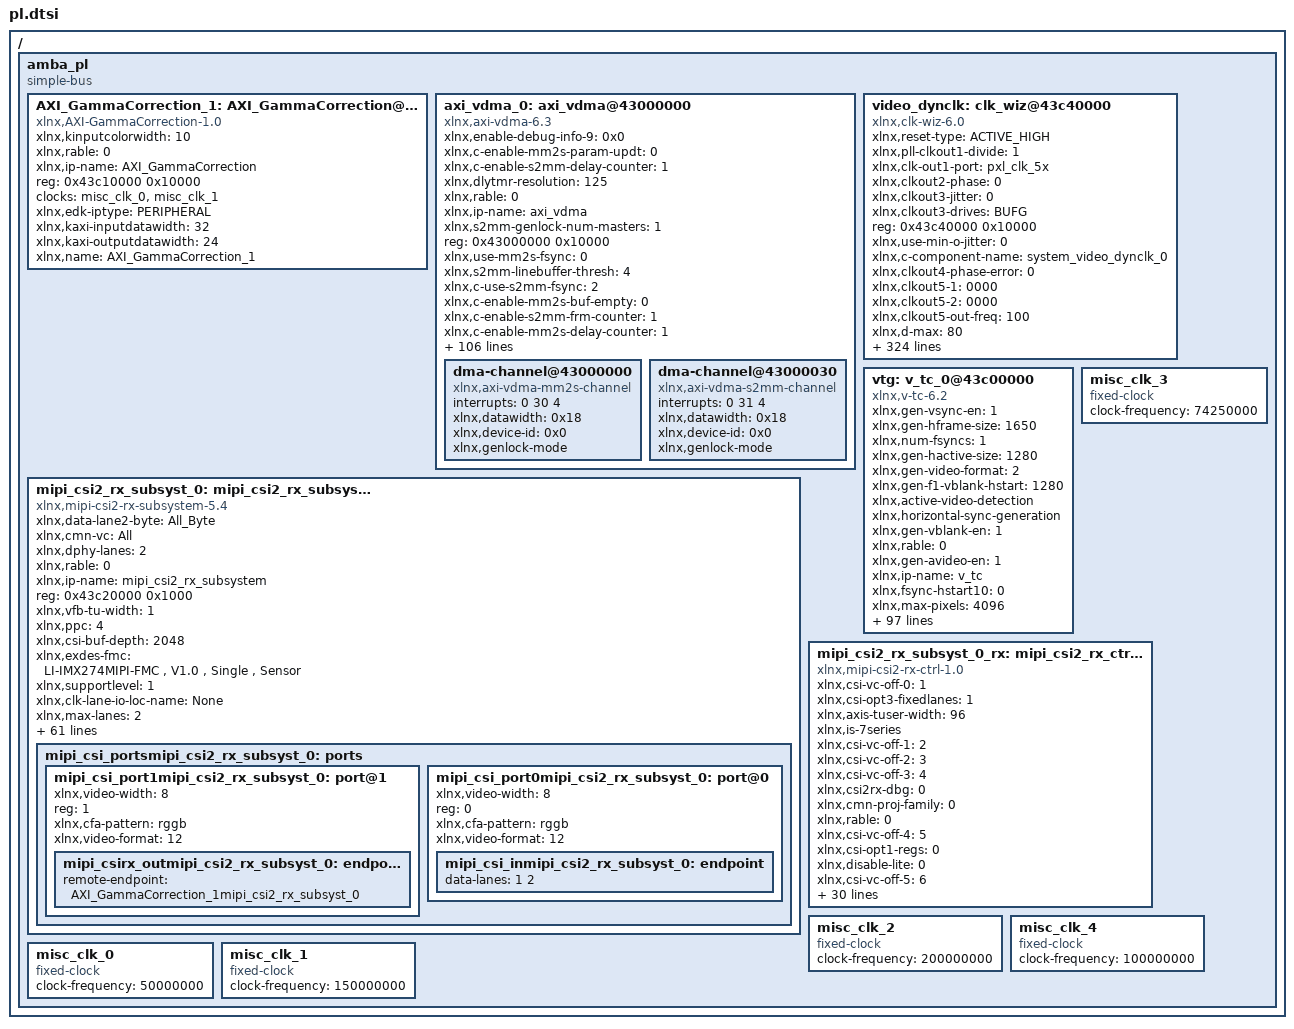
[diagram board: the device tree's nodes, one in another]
/ {
	amba_pl: amba_pl {
		ranges;
		compatible = "simple-bus";
		#address-cells = <1>;
		#size-cells = <1>;
		AXI_GammaCorrection_1: AXI_GammaCorrection@43c10000 {
			compatible = "xlnx,AXI-GammaCorrection-1.0";
			xlnx,kinputcolorwidth = <10>;
			xlnx,rable = <0>;
			xlnx,ip-name = "AXI_GammaCorrection";
			reg = <0x43c10000 0x10000>;
			clocks = <&misc_clk_0>, <&misc_clk_1>;
			xlnx,edk-iptype = "PERIPHERAL";
			xlnx,kaxi-inputdatawidth = <32>;
			xlnx,kaxi-outputdatawidth = <24>;
			status = "okay";
			clock-names = "AxiLiteClk" , "StreamClk";
			xlnx,name = "AXI_GammaCorrection_1";
		};
		axi_vdma_0: axi_vdma@43000000 {
			xlnx,enable-debug-info-9 = <0x0>;
			xlnx,c-enable-mm2s-param-updt = <0>;
			xlnx,c-enable-s2mm-delay-counter = <1>;
			xlnx,dlytmr-resolution = <125>;
			xlnx,rable = <0>;
			xlnx,ip-name = "axi_vdma";
			xlnx,s2mm-genlock-num-masters = <1>;
			reg = <0x43000000 0x10000>;
			xlnx,use-mm2s-fsync = <0>;
			xlnx,s2mm-linebuffer-thresh = <4>;
			xlnx,c-use-s2mm-fsync = <2>;
			xlnx,c-enable-mm2s-buf-empty = <0>;
			xlnx,c-enable-s2mm-frm-counter = <1>;
			xlnx,c-enable-mm2s-delay-counter = <1>;
			xlnx,c-dlytmr-resolution = <125>;
			xlnx,c-enable-s2mm-buf-full = <0>;
			xlnx,dynamic-resolution = <1>;
			interrupt-names = "mm2s_introut" , "s2mm_introut";
			xlnx,s2mm-sof-enable = <0x1>;
			xlnx,mm2s-genlock-num-masters = <1>;
			xlnx,c-s2mm-genlock-num-masters = <1>;
			xlnx,c-enable-s2mm-fsync-out = <0>;
			xlnx,mm2s-linebuffer-thresh = <4>;
			xlnx,c-use-mm2s-fsync = <0>;
			xlnx,c-s2mm-linebuffer-thresh = <4>;
			xlnx,c-enable-mm2s-frm-counter = <1>;
			compatible = "xlnx,axi-vdma-6.3" , "xlnx,axi-vdma-1.00.a";
			xlnx,c-m-axis-mm2s-tdata-width = <24>;
			xlnx,c-enable-all = <0>;
			interrupt-parent = <&intc>;
			xlnx,s2mm-max-burst-length = <8>;
			xlnx,c-dynamic-resolution = <1>;
			xlnx,c-enable-s2mm-rst-out = <0>;
			xlnx,mm2s-sof-enable = <1>;
			xlnx,include-s2mm-dre = <0x0>;
			xlnx,c-s2mm-sof-enable = <1>;
			xlnx,c-enable-mm2s-fsync-out = <0>;
			xlnx,c-mm2s-genlock-num-masters = <1>;
			xlnx,c-mm2s-linebuffer-thresh = <4>;
			xlnx,c-enable-tstvec = <0>;
			xlnx,mm2s-max-burst-length = <8>;
			xlnx,c-s2mm-max-burst-length = <8>;
			status = "okay";
			xlnx,c-enable-mm2s-rst-out = <0>;
			xlnx,include-mm2s-dre = <0x0>;
			xlnx,c-include-s2mm-dre = <0>;
			xlnx,c-mm2s-sof-enable = <1>;
			xlnx,name = "axi_vdma_0";
			xlnx,c-enable-s2mm-frmstr-reg = <0>;
			interrupts = < 0 30 4 0 31 4 >;
			xlnx,c-include-sg = <0>;
			xlnx,flush-on-fsync = <0x1>;
			xlnx,c-m-axi-s2mm-data-width = <64>;
			xlnx,c-enable-s2mm-sts-reg = <0>;
			xlnx,include-s2mm-sf = <1>;
			xlnx,c-mm2s-max-burst-length = <8>;
			xlnx,s2mm-linebuffer-depth = <0x400>;
			xlnx,include-s2mm = <0x1>;
			xlnx,c-include-mm2s-dre = <0>;
			clocks = <&misc_clk_1>, <&misc_clk_1>, <&misc_clk_1>, <&misc_clk_0>, <&misc_clk_1>;
			xlnx,c-enable-mm2s-frmstr-reg = <0>;
			xlnx,enable-debug-info-10 = <0>;
			xlnx,addrwidth = <0x20>;
			xlnx,enable-debug-info-11 = <0>;
			xlnx,enable-debug-info-12 = <0>;
			xlnx,edk-iptype = "PERIPHERAL";
			xlnx,c-flush-on-fsync = <1>;
			xlnx,c-m-axi-mm2s-data-width = <64>;
			xlnx,use-fsync = <1>;
			xlnx,s2mm-genlock-repeat-en = <1>;
			xlnx,enable-vert-flip = <0x0>;
			xlnx,enable-debug-info-13 = <0x0>;
			xlnx,include-mm2s-sf = <0>;
			xlnx,include-internal-genlock = <0x1>;
			xlnx,enable-debug-info-14 = <0x1>;
			xlnx,c-include-s2mm-sf = <1>;
			clock-names = "m_axi_mm2s_aclk" , "m_axi_s2mm_aclk" , "m_axis_mm2s_aclk" , "s_axi_lite_aclk" , "s_axis_s2mm_aclk";
			xlnx,enable-debug-info-15 = <0x1>;
			xlnx,mm2s-linebuffer-depth = <0x400>;
			xlnx,include-mm2s = <0x1>;
			xlnx,c-single-interface = <0>;
			xlnx,c-s2mm-linebuffer-depth = <1024>;
			xlnx,c-addr-width = <32>;
			xlnx,c-include-s2mm = <1>;
			xlnx,s2mm-genlock-mode = <0x2>;
			xlnx,c-s-axis-s2mm-tdata-width = <24>;
			xlnx,flush-fsync = <0x1>;
			xlnx,select-xpm = <0>;
			xlnx,s2mm-data-width = <0x40>;
			xlnx,num-fstores = <0x3>;
			xlnx,enable-vidparam-reads = <0x1>;
			xlnx,mm2s-genlock-repeat-en = <0>;
			xlnx,c-use-fsync = <1>;
			xlnx,c-s2mm-genlock-repeat-en = <1>;
			xlnx,c-enable-vert-flip = <0>;
			xlnx,prmry-is-aclk-async = <0>;
			xlnx,c-include-internal-genlock = <1>;
			xlnx,c-include-mm2s-sf = <0>;
			xlnx,s2mm-tdata-width = <0x18>;
			xlnx,enable-vidprmtr-reads = <1>;
			xlnx,c-include-mm2s = <1>;
			xlnx,c-mm2s-linebuffer-depth = <1024>;
			xlnx,mm2s-genlock-mode = <0x3>;
			xlnx,enable-debug-info-0 = <0>;
			xlnx,enable-debug-all = <0x0>;
			xlnx,c-s2mm-genlock-mode = <2>;
			xlnx,enable-debug-info-1 = <0x0>;
			xlnx,mm2s-data-width = <0x40>;
			xlnx,enable-debug-info-2 = <0>;
			xlnx,c-enable-s2mm-param-updt = <0>;
			xlnx,c-num-fstores = <3>;
			xlnx,enable-debug-info-3 = <0>;
			xlnx,enable-debug-info-4 = <0>;
			xlnx,c-mm2s-genlock-repeat-en = <0>;
			xlnx,enable-debug-info-5 = <0x0>;
			xlnx,c-prmry-is-aclk-async = <0>;
			xlnx,mm2s-tdata-width = <0x18>;
			xlnx,enable-debug-info-6 = <0x1>;
			xlnx,enable-debug-info-7 = <0x1>;
			xlnx,c-enable-vidprmtr-reads = <1>;
			xlnx,use-s2mm-fsync = <2>;
			xlnx,enable-debug-info-8 = <0>;
			xlnx,c-mm2s-genlock-mode = <3>;
			dma-channel@43000000 {
				interrupts = < 0 30 4 >;
				xlnx,datawidth = <0x18>;
				xlnx,device-id = <0x0>;
				compatible = "xlnx,axi-vdma-mm2s-channel";
				xlnx,genlock-mode;
			};
			dma-channel@43000030 {
				interrupts = < 0 31 4 >;
				xlnx,datawidth = <0x18>;
				xlnx,device-id = <0x0>;
				compatible = "xlnx,axi-vdma-s2mm-channel";
				xlnx,genlock-mode;
			};
		};
		mipi_csi2_rx_subsyst_0: mipi_csi2_rx_subsystem@43c20000 {
			xlnx,data-lane2-byte = "All_Byte";
			xlnx,cmn-vc = "All";
			xlnx,dphy-lanes = <2>;
			xlnx,rable = <0>;
			xlnx,ip-name = "mipi_csi2_rx_subsystem";
			reg = <0x43c20000 0x1000>;
			xlnx,vfb-tu-width = <1>;
			xlnx,ppc = <4>;
			xlnx,csi-buf-depth = <2048>;
			xlnx,exdes-fmc = "LI-IMX274MIPI-FMC , V1.0 , Single , Sensor";
			xlnx,supportlevel = <1>;
			xlnx,clk-lane-io-loc-name = "None";
			xlnx,max-lanes = <2>;
			xlnx,clk-lane-io-loc = "None";
			xlnx,esc-timeout = <25600>;
			xlnx,cmn-inc-vfb;
			xlnx,axis-tuser-width = <96>;
			compatible = "xlnx,mipi-csi2-rx-subsystem-5.4" , "xlnx,mipi-csi2-rx-subsystem-5.0";
			xlnx,is-7series;
			xlnx,idly-tap = <1>;
			xlnx,fifo-rd-en-control;
			xlnx,cmn-num-pixels = <4>;
			xlnx,cmn-proj-family = <0>;
			xlnx,csi2rx-dbg = <0>;
			xlnx,vfb;
			xlnx,data-lane1-io-loc-name = "None";
			xlnx,hs-timeout = <65541>;
			xlnx,ext-mmcm = <0>;
			xlnx,data-lane3-io-loc-name = "None";
			xlnx,data-lane1-byte = "All_Byte";
			xlnx,cal-mode = "NONE";
			status = "okay";
			xlnx,data-lane0-io-position = <2>;
			xlnx,exdes-board = "SP701";
			xlnx,data-lane2-io-position = <6>;
			xlnx,vc = <4>;
			xlnx,name = "mipi_csi2_rx_subsyst_0";
			xlnx,data-lane3-io-loc = "None";
			xlnx,dphyrx-board-interface = "Custom";
			xlnx,hs-settle-ns = <147>;
			clocks = <&misc_clk_2>, <&misc_clk_0>, <&misc_clk_1>;
			xlnx,mipi-slv-int = <0>;
			xlnx,data-lane2-io-loc = "None";
			xlnx,cmn-fifo-rd-en-cntrl;
			xlnx,stretch-line-rate = <3500>;
			xlnx,axis-tdest-width = <4>;
			xlnx,data-lane3-byte = "All_Byte";
			xlnx,init = <100000>;
			xlnx,edk-iptype = "PERIPHERAL";
			xlnx,int-qor-check = <0>;
			xlnx,cmn-pxl-format = "RAW10";
			clock-names = "dphy_clk_200M" , "lite_aclk" , "video_aclk";
			xlnx,ooc-vid-clk = <0x65b710>;
			xlnx,data-lane0-byte = "All_Byte";
			xlnx,data-lane1-io-loc = "None";
			xlnx,yuv420-buf-dpth = <128>;
			xlnx,hp-io-bank-selection = <64>;
			xlnx,lprx-disable-extport = <0>;
			xlnx,idly-group-name = "mipi_csi2rx_idly_group";
			xlnx,cmn-num-lanes = <2>;
			xlnx,exdesboard-version = <2>;
			xlnx,exdes-config = "MIPI_Video_Pipe_Camera_to_Display";
			xlnx,data-lane0-io-loc-name = "None";
			xlnx,dphy-preset = "CSI2RX_XLNX";
			xlnx,csi-pxl-format = <0x2b>;
			xlnx,clk-lane-io-position = <0>;
			xlnx,data-lane0-io-loc = "None";
			xlnx,data-lane2-io-loc-name = "None";
			xlnx,hs-line-rate = <800>;
			xlnx,dpy-line-rate = <800>;
			xlnx,csi-en-crc;
			xlnx,axis-tdata-width = <32>;
			xlnx,csi-controller-reg-if;
			xlnx,data-lane1-io-position = <4>;
			xlnx,dphy-mode = "SLAVE";
			xlnx,data-lane3-io-position = <8>;
			mipi_csi_portsmipi_csi2_rx_subsyst_0: ports {
				#address-cells = <1>;
				#size-cells = <0>;
				mipi_csi_port1mipi_csi2_rx_subsyst_0: port@1 {
					xlnx,video-width = <8>;
					reg = <1>;
					xlnx,cfa-pattern = "rggb";
					xlnx,video-format = <12>;
					mipi_csirx_outmipi_csi2_rx_subsyst_0: endpoint {
						remote-endpoint = <&AXI_GammaCorrection_1mipi_csi2_rx_subsyst_0>;
					};
				};
				mipi_csi_port0mipi_csi2_rx_subsyst_0: port@0 {
					xlnx,video-width = <8>;
					reg = <0>;
					xlnx,cfa-pattern = "rggb";
					xlnx,video-format = <12>;
					mipi_csi_inmipi_csi2_rx_subsyst_0: endpoint {
						data-lanes = "1 2";
					};
				};
			};
		};
		video_dynclk: clk_wiz@43c40000 {
			xlnx,reset-type = "ACTIVE_HIGH";
			xlnx,pll-clkout1-divide = <1>;
			xlnx,clk-out1-port = "pxl_clk_5x";
			xlnx,clkout2-phase = <0>;
			xlnx,clkout3-jitter = <0>;
			xlnx,clkout3-drives = "BUFG";
			reg = <0x43c40000 0x10000>;
			xlnx,use-min-o-jitter = <0>;
			xlnx,c-component-name = "system_video_dynclk_0";
			xlnx,clkout4-phase-error = <0>;
			xlnx,clkout5-1 = <0000>;
			xlnx,clkout5-2 = <0000>;
			xlnx,clkout5-out-freq = <100>;
			xlnx,d-max = <80>;
			xlnx,clkout1-phase = <0>;
			xlnx,divide6-auto = <1>;
			xlnx,clkout1-jitter = <0xddc1c68>;
			xlnx,clkfb-in-n-port = "clkfb_in_n";
			xlnx,clkout2-requested-out-freq = <100>;
			xlnx,use-locked = <1>;
			xlnx,pll-clkout5-duty-cycle = <0x7a120>;
			xlnx,mmcm-clkout3-use-fine-ps;
			xlnx,clkout1-drives = "No_buffer";
			xlnx,input-clk-stopped-port = "input_clk_stopped";
			xlnx,clkout4-duty-cycle = <50>;
			xlnx,divide3-auto = <1>;
			xlnx,use-dyn-reconfig = <1>;
			xlnx,clkout3-actual-freq = <100>;
			xlnx,clkout6-requested-duty-cycle = <50>;
			xlnx,diff-clk-in1-board-interface = "Custom";
			xlnx,mmcm-clkout0-duty-cycle = <0x7a120>;
			xlnx,clkin2-jitter-ps = <100>;
			xlnx,clkout2-1 = <0000>;
			xlnx,in-freq-units = "Units_MHz";
			xlnx,clkout2-2 = <0000>;
			xlnx,feedback-source = "FDBK_ONCHIP";
			xlnx,clkout5-requested-out-freq = <100>;
			xlnx,name = "video_dynclk";
			xlnx,prim-in-freq = <100>;
			xlnx,mmcm-clkout5-divide = <1>;
			xlnx,clkout3-phase-error = <0>;
			xlnx,clk-in2-board-interface = "Custom";
			xlnx,clkin1-ui-jitter = <0x2710>;
			xlnx,use-inclk-switchover = <0>;
			clock-names = "clk_in1" , "s_axi_aclk";
			xlnx,clkout5-duty-cycle = <50>;
			xlnx,use-clkout4-bar = <0>;
			xlnx,mmcm-clkout1-duty-cycle = <0x7a120>;
			xlnx,mmcm-clkout2-use-fine-ps;
			xlnx,clkout2-out-freq = <100>;
			xlnx,use-dyn-phase-shift = <0>;
			xlnx,mmcm-clkout3-divide = <1>;
			xlnx,clkout2-actual-freq = <100>;
			xlnx,o-min = <1>;
			xlnx,daddr-port = "daddr";
			xlnx,precision = <1>;
			xlnx,mmcm-ref-jitter1 = <0x2710>;
			clock-output-names = "0x43c40000-pxl_clk_5x";
			xlnx,mmcm-ref-jitter2 = <0x2710>;
			xlnx,pll-notes = "No , notes";
			xlnx,use-phase-alignment = <0>;
			xlnx,ref-clk-freq = <100>;
			xlnx,clkout7-requested-duty-cycle = <50>;
			xlnx,inclk-sum-row0 = "Input , Clock , Freq , (MHz) , Input , Jitter , (UI)";
			xlnx,inclk-sum-row1 = "__primary_________100.000____________0.010";
			xlnx,use-fast-simulation = <0>;
			xlnx,inclk-sum-row2 = "no_secondary_input_clock";
			xlnx,mmcm-clkout1-divide = <1>;
			xlnx,din-port = "din";
			xlnx,reset-board-interface = "Custom";
			xlnx,clkout6-duty-cycle = <50>;
			xlnx,clkout2-phase-error = <0>;
			xlnx,clkout1-requested-duty-cycle = <50>;
			xlnx,vco-max = <1200>;
			xlnx,use-freq-synth = <1>;
			xlnx,primtype-sel = "AUTO";
			xlnx,mmcm-clkout2-duty-cycle = <0x7a120>;
			xlnx,clkout5-used = <0>;
			xlnx,d-min = <1>;
			xlnx,pll-clkfbout-mult = <1>;
			xlnx,mmcm-clkout4-cascade;
			xlnx,use-clkout1-bar = <0>;
			xlnx,clk-out6-port = "clk_out6";
			xlnx,clkout2-sequence-number = <1>;
			xlnx,clk-valid-port = "CLK_VALID";
			xlnx,clkout2-used = <0>;
			xlnx,clkout4-sequence-number = <1>;
			speed-grade = <1>;
			xlnx,psincdec-port = "psincdec";
			xlnx,mmcm-clkout1-use-fine-ps;
			xlnx,clk-out3-port = "clk_out3";
			xlnx,clkout6-sequence-number = <1>;
			xlnx,platform = "UNKNOWN";
			xlnx,mmcm-clkout6-phase = <0>;
			xlnx,clkout1-actual-freq = <100>;
			xlnx,clkout6-out-freq = <100>;
			xlnx,mmcm-clkin2-period = <10>;
			xlnx,prim-in-jitter = <0x2710>;
			xlnx,mmcm-clkfbout-mult-f = <0x2367b88>;
			status = "okay";
			xlnx,clkout6-1 = <0000>;
			xlnx,clkout6-2 = <0000>;
			xlnx,clkout7-duty-cycle = <50>;
			xlnx,outclk-sum-row1 = "pxl_clk_5x__742.50000______0.000______50.0______232.529____322.999";
			xlnx,outclk-sum-row2 = "no_CLK_OUT2_output";
			xlnx,jitter-sel = "No_Jitter";
			xlnx,outclk-sum-row3 = "no_CLK_OUT3_output";
			xlnx,mmcm-clkout5-phase = <0>;
			xlnx,mmcm-clkout3-duty-cycle = <0x7a120>;
			xlnx,outclk-sum-row4 = "no_CLK_OUT4_output";
			xlnx,clkfb-in-p-port = "clkfb_in_p";
			xlnx,outclk-sum-row5 = "no_CLK_OUT5_output";
			xlnx,outclk-sum-row6 = "no_CLK_OUT6_output";
			xlnx,outclk-sum-row7 = "no_CLK_OUT7_output";
			xlnx,clkout1-phase-error = <0x134092d8>;
			xlnx,divide5-auto = <1>;
			xlnx,pll-bandwidth = "OPTIMIZED";
			xlnx,psdone-port = "psdone";
			xlnx,clkout3-1 = <0000>;
			xlnx,clkout3-2 = <0000>;
			xlnx,clkout3-requested-out-freq = <100>;
			xlnx,edk-iptype = "PERIPHERAL";
			xlnx,pll-clkout4-divide = <1>;
			xlnx,pll-clkfbout-phase = <0>;
			xlnx,divide2-auto = <1>;
			xlnx,override-mmcm = <0>;
			xlnx,clkout6-jitter = <0>;
			xlnx,ss-mode = "CENTER_HIGH";
			xlnx,mmcm-notes = "None";
			xlnx,mmcm-clkout0-use-fine-ps;
			xlnx,clkout6-drives = "BUFG";
			xlnx,mmcm-clkfbout-use-fine-ps;
			xlnx,ss-mod-period = <4000>;
			xlnx,mmcm-clkout4-phase = <0>;
			xlnx,clkout2-requested-duty-cycle = <50>;
			xlnx,clkout0-actual-freq = <0x2c41a6a0>;
			xlnx,divclk = <0000>;
			xlnx,primary-port = "clk_in1";
			xlnx,mmcm-compensation = "ZHOLD";
			xlnx,clkout6-requested-out-freq = <100>;
			xlnx,clkout0-1 = <0000>;
			xlnx,clkout0-2 = <0000>;
			xlnx,clkout2-requested-phase = <0>;
			xlnx,relative-inclk = "REL_PRIMARY";
			xlnx,pll-clkout2-divide = <1>;
			xlnx,clkout4-requested-phase = <0>;
			xlnx,enable-user-clock0 = <0>;
			xlnx,filter-1 = <0000>;
			xlnx,mmcm-clkout4-duty-cycle = <0x7a120>;
			xlnx,clkout3-out-freq = <100>;
			xlnx,clkout4-jitter = <0>;
			xlnx,clkout6-requested-phase = <0>;
			xlnx,clkoutphy-requested-freq = <600>;
			xlnx,enable-user-clock1 = <0>;
			xlnx,filter-2 = <0000>;
			xlnx,ss-mod-freq = <250>;
			xlnx,mmcm-divclk-divide = <5>;
			xlnx,enable-user-clock2 = <0>;
			xlnx,in-jitter-units = "Units_UI";
			xlnx,enable-user-clock3 = <0>;
			xlnx,lock-1 = <0000>;
			xlnx,clkout4-drives = "BUFG";
			xlnx,lock-2 = <0000>;
			xlnx,den-port = "den";
			xlnx,lock-3 = <0000>;
			xlnx,use-safe-clock-startup = <0>;
			xlnx,mmcm-clkout3-phase = <0>;
			xlnx,dwe-port = "dwe";
			xlnx,clkfb-out-n-port = "clkfb_out_n";
			xlnx,use-max-i-jitter = <0>;
			xlnx,drdy-port = "drdy";
			xlnx,vco-min = <600>;
			xlnx,pll-clkout0-divide = <1>;
			xlnx,clkin1-jitter-ps = <100>;
			xlnx,clk-in-sel-port = "clk_in_sel";
			xlnx,use-freeze = <0>;
			xlnx,clkout2-jitter = <0>;
			xlnx,enable-pll0 = <0>;
			xlnx,enable-pll1 = <0>;
			xlnx,clkout2-drives = "BUFG";
			xlnx,use-inclk-stopped = <0>;
			xlnx,use-clkout3-bar = <0>;
			xlnx,use-clk-valid = <0>;
			xlnx,mmcm-clkout2-phase = <0>;
			compatible = "xlnx,clk-wiz-6.0" , "xlnx,clocking-wizard";
			xlnx,reset-port = "reset";
			xlnx,mmcm-clkout5-duty-cycle = <0x7a120>;
			xlnx,mmcm-clkout0-divide-f = <1>;
			xlnx,pll-clkout0-duty-cycle = <0x7a120>;
			xlnx,diff-clk-in2-board-interface = "Custom";
			xlnx,clkout3-requested-duty-cycle = <50>;
			xlnx,use-status = <0>;
			xlnx,prim-source = "No_buffer";
			xlnx,clkout7-used = <0>;
			xlnx,use-clkfb-stopped = <0>;
			xlnx,mmcm-clkout1-phase = <0>;
			xlnx,mmcm-clkout6-divide = <1>;
			xlnx,clkout7-out-freq = <100>;
			xlnx,prim-in-timeperiod = <10>;
			xlnx,clkout4-used = <0>;
			xlnx,pll-clkin-period = <1>;
			xlnx,clk-out5-port = "clk_out5";
			xlnx,psclk-port = "psclk";
			xlnx,primitive = "MMCM";
			xlnx,clkout1-used;
			xlnx,reset-low = <0>;
			xlnx,clk-in1-board-interface = "Custom";
			xlnx,clk-out2-port = "clk_out2";
			xlnx,power-down-port = "power_down";
			xlnx,clkout7-phase-error = <0>;
			xlnx,mmcm-clkout6-duty-cycle = <0x7a120>;
			xlnx,mmcm-clkout4-divide = <1>;
			xlnx,mmcm-clkfbout-phase = <0>;
			xlnx,mmcm-clkout0-phase = <0>;
			xlnx,pll-clkout1-duty-cycle = <0x7a120>;
			xlnx,user-clk-freq0 = <100>;
			xlnx,user-clk-freq1 = <100>;
			xlnx,pll-clkout5-phase = <0>;
			xlnx,user-clk-freq2 = <100>;
			xlnx,secondary-in-jitter = <0x2710>;
			xlnx,user-clk-freq3 = <100>;
			xlnx,use-clock-sequencing = <0>;
			xlnx,secondary-source = "Single_ended_clock_capable_pin";
			xlnx,cddcdone-port = "cddcdone";
			xlnx,clkout7-phase = <0>;
			xlnx,psen-port = "psen";
			xlnx,mmcm-clkout6-use-fine-ps;
			xlnx,dclk-port = "dclk";
			xlnx,m-max = <64>;
			xlnx,outclk-sum-row0a = "Output , Output , Phase , Duty , Cycle , Pk-to-Pk , Phase";
			xlnx,clkout1-requested-out-freq = <0x2c41a6a0>;
			xlnx,clkout6-actual-freq = <100>;
			xlnx,divide7-auto = <1>;
			xlnx,outclk-sum-row0b = "Clock , Freq , (MHz) , (degrees) , (%) , Jitter , (ps) , Error , (ps)";
			xlnx,clkout4-1 = <0000>;
			xlnx,locked-port = "locked";
			xlnx,mmcm-clkout2-divide = <1>;
			xlnx,clkin2-ui-jitter = <0x2710>;
			xlnx,clkout4-2 = <0000>;
			xlnx,enable-clock-monitor = <0>;
			xlnx,ss-mod-time = <0xfa0>;
			xlnx,auto-primitive = "MMCM";
			xlnx,divide4-auto = <1>;
			xlnx,pll-clkout4-phase = <0>;
			xlnx,use-power-down = <0>;
			xlnx,mmcm-startup-wait;
			xlnx,divide1-auto = <1>;
			xlnx,clkout4-requested-duty-cycle = <50>;
			xlnx,clkout4-requested-out-freq = <100>;
			xlnx,rable = <0>;
			xlnx,optimize-clocking-structure-en = <0>;
			xlnx,clkout4-out-freq = <100>;
			xlnx,clkout6-phase = <0>;
			xlnx,num-out-clks = <1>;
			xlnx,ip-name = "clk_wiz";
			xlnx,pll-clkout2-duty-cycle = <0x7a120>;
			xlnx,clkout1-1 = <0000>;
			xlnx,clkout1-2 = <0000>;
			xlnx,clkout1-duty-cycle = <50>;
			xlnx,pll-divclk-divide = <1>;
			xlnx,clkout6-phase-error = <0>;
			xlnx,dout-port = "dout";
			xlnx,clkout1-sequence-number = <1>;
			xlnx,pll-clkout3-phase = <0>;
			xlnx,cddcreq-port = "cddcreq";
			xlnx,clkout7-requested-out-freq = <100>;
			xlnx,use-spread-spectrum = <0>;
			xlnx,clkout3-sequence-number = <1>;
			xlnx,clkout5-sequence-number = <1>;
			xlnx,summary-strings = "empty";
			xlnx,pll-compensation = "SYSTEM_SYNCHRONOUS";
			xlnx,clkout5-phase = <0>;
			xlnx,clkout7-sequence-number = <1>;
			xlnx,status-port = "STATUS";
			xlnx,clkfb-out-p-port = "clkfb_out_p";
			xlnx,mmcm-clkout5-use-fine-ps;
			xlnx,clkfb-in-port = "clkfb_in";
			xlnx,clkout5-actual-freq = <100>;
			xlnx,input-mode = "frequency";
			xlnx,interface-selection = <1>;
			xlnx,mmcm-bandwidth = "OPTIMIZED";
			xlnx,calc-done = "empty";
			xlnx,pll-clkout2-phase = <0>;
			xlnx,has-cddc = <0>;
			xlnx,power-reg = <0000>;
			xlnx,mmcm-clkin1-period = <10>;
			xlnx,pll-clkout3-duty-cycle = <0x7a120>;
			xlnx,clkout2-duty-cycle = <50>;
			xlnx,clkout4-phase = <0>;
			xlnx,pll-clkout5-divide = <1>;
			xlnx,clkout7-jitter = <0>;
			clocks = <&clkc 15>, <&misc_clk_0>;
			xlnx,clkout1-out-freq = <0x2c41a6a0>;
			xlnx,clkout7-drives = "BUFG";
			xlnx,clkout5-phase-error = <0>;
			xlnx,pll-clkout1-phase = <0>;
			xlnx,clkout5-requested-duty-cycle = <50>;
			xlnx,clkfb-in-signaling = "SINGLE";
			xlnx,enable-clkoutphy = <0>;
			xlnx,use-clkout2-bar = <0>;
			xlnx,secondary-port = "clk_in2";
			xlnx,clkout3-phase = <0>;
			xlnx,pll-clkout3-divide = <1>;
			xlnx,use-reset = <1>;
			xlnx,override-pll = <0>;
			xlnx,clkoutphy-mode = "VCO";
			xlnx,mmcm-clkout4-use-fine-ps;
			xlnx,clkout5-jitter = <0>;
			xlnx,clkout6-used = <0>;
			xlnx,m-min = <2>;
			xlnx,mmcm-clock-hold;
			xlnx,clkfb-stopped-port = "clkfb_stopped";
			xlnx,clk-out7-port = "clk_out7";
			xlnx,clkout1-requested-phase = <0>;
			xlnx,clkout4-actual-freq = <100>;
			xlnx,pll-clk-feedback = "CLKFBOUT";
			xlnx,phaseshift-mode = "WAVEFORM";
			xlnx,clkfb-out-port = "clkfb_out";
			xlnx,clkout5-drives = "BUFG";
			xlnx,o-max = <128>;
			xlnx,clkout3-requested-phase = <0>;
			xlnx,secondary-in-timeperiod = <10>;
			xlnx,pll-clkout4-duty-cycle = <0x7a120>;
			xlnx,clkout3-used = <0>;
			xlnx,jitter-options = "UI";
			xlnx,clkout5-requested-phase = <0>;
			xlnx,pll-clkout0-phase = <0>;
			xlnx,clk-out4-port = "clk_out4";
			xlnx,clkout3-duty-cycle = <50>;
			xlnx,clkout7-requested-phase = <0>;
			xlnx,secondary-in-freq = <100>;
			xlnx,use-min-power = <0>;
			xlnx,clkfbout-1 = <0000>;
			#clock-cells = <1>;
			xlnx,pll-ref-jitter = <0x2710>;
			xlnx,clkfbout-2 = <0000>;
		};
		vtg: v_tc_0@43c00000 {
			xlnx,gen-vsync-en = <1>;
			xlnx,gen-hframe-size = <1650>;
			xlnx,num-fsyncs = <1>;
			xlnx,gen-hactive-size = <1280>;
			xlnx,gen-video-format = <2>;
			xlnx,gen-f1-vblank-hstart = <1280>;
			xlnx,active-video-detection;
			xlnx,horizontal-sync-generation;
			xlnx,gen-vblank-en = <1>;
			xlnx,rable = <0>;
			xlnx,gen-avideo-en = <1>;
			xlnx,ip-name = "v_tc";
			xlnx,fsync-hstart10 = <0>;
			xlnx,max-pixels = <4096>;
			xlnx,gen-fieldid-en = <0>;
			reg = <0x43c00000 0x10000>;
			xlnx,det-vblank-en = <1>;
			xlnx,fsync-hstart11 = <0>;
			xlnx,fsync-hstart12 = <0>;
			xlnx,gen-interlaced = <0>;
			xlnx,det-avideo-en = <1>;
			xlnx,fsync-hstart13 = <0>;
			xlnx,fsync-hstart14 = <0>;
			xlnx,gen-f0-vblank-hend = <1280>;
			xlnx,fsync-hstart15 = <0>;
			xlnx,det-hsync-en = <1>;
			interrupt-names = "irq";
			xlnx,gen-avideo-polarity = <1>;
			xlnx,enable-generation;
			xlnx,max-lines-per-frame = <4096>;
			xlnx,has-axi4-lite = <1>;
			compatible = "xlnx,v-tc-6.2" , "xlnx,v-tc-6.1";
			xlnx,max-clocks-per-line = <4096>;
			xlnx,gen-f0-vframe-size = <750>;
			xlnx,gen-f0-vblank-hstart = <1280>;
			interrupt-parent = <&intc>;
			xlnx,max-lines = <4096>;
			xlnx,gen-f0-vsync-vstart = <724>;
			xlnx,horizontal-blank-generation;
			xlnx,gen-hsync-end = <1430>;
			xlnx,gen-f0-vsync-hstart = <1280>;
			xlnx,gen-f1-vsync-hend = <1280>;
			xlnx,vertical-blank-detection;
			xlnx,gen-vsync-polarity = <1>;
			xlnx,fsync-vstart0 = <0>;
			xlnx,gen-hsync-polarity = <1>;
			xlnx,fsync-vstart1 = <0>;
			status = "okay";
			xlnx,fsync-vstart2 = <0>;
			xlnx,gen-hsync-start = <1390>;
			xlnx,gen-f0-vsync-vend = <729>;
			xlnx,fsync-vstart3 = <0>;
			xlnx,vertical-sync-detection;
			xlnx,frame-syncs = <1>;
			xlnx,fsync-vstart4 = <0>;
			xlnx,gen-vactive-size = <720>;
			xlnx,name = "vtg";
			xlnx,fsync-vstart5 = <0>;
			interrupts = < 0 29 4 >;
			xlnx,gen-achroma-en = <0>;
			xlnx,fsync-vstart6 = <0>;
			xlnx,fsync-vstart7 = <0>;
			xlnx,det-fieldid-en = <0>;
			xlnx,gen-hsync-en = <1>;
			xlnx,fsync-vstart8 = <0>;
			xlnx,fsync-vstart9 = <0>;
			xlnx,fsync-vstart10 = <0>;
			xlnx,fsync-vstart11 = <0>;
			xlnx,arbitrary-res-en = <0>;
			xlnx,fsync-vstart12 = <0>;
			xlnx,fsync-vstart13 = <0>;
			clocks = <&misc_clk_3>, <&misc_clk_0>;
			xlnx,fsync-vstart14 = <0>;
			xlnx,fsync-vstart15 = <0>;
			xlnx,gen-cparity = <0>;
			xlnx,edk-iptype = "PERIPHERAL";
			xlnx,vertical-sync-generation;
			xlnx,gen-f1-vblank-hend = <1280>;
			xlnx,det-vsync-en = <1>;
			xlnx,gen-vblank-polarity = <1>;
			xlnx,fsync-hstart0 = <0>;
			clock-names = "clk" , "s_axi_aclk";
			xlnx,interlace-en = <0>;
			xlnx,gen-auto-switch = <0>;
			xlnx,fsync-hstart1 = <0>;
			xlnx,fsync-hstart2 = <0>;
			xlnx,active-video-generation;
			xlnx,fsync-hstart3 = <0>;
			xlnx,fsync-hstart4 = <0>;
			xlnx,horizontal-blank-detection;
			xlnx,fsync-hstart5 = <0>;
			xlnx,gen-f1-vframe-size = <750>;
			xlnx,fsync-hstart6 = <0>;
			xlnx,fsync-hstart7 = <0>;
			xlnx,fsync-hstart8 = <0>;
			xlnx,gen-hblank-en = <1>;
			xlnx,fsync-hstart9 = <0>;
			xlnx,horizontal-sync-detection;
			xlnx,gen-f1-vsync-vend = <729>;
			xlnx,detect-en = <0>;
			xlnx,det-hblank-en = <1>;
			xlnx,vid-ppc = <4>;
			xlnx,has-intc-if = <0>;
			xlnx,generate-en = <1>;
			xlnx,gen-achroma-polarity = <1>;
			xlnx,sync-en = <0>;
			xlnx,det-achroma-en = <0>;
			xlnx,generator;
			xlnx,gen-f1-vsync-vstart = <724>;
			xlnx,vertical-blank-generation;
			xlnx,gen-hblank-polarity = <1>;
			xlnx,video-mode = "720p";
			xlnx,gen-fieldid-polarity = <1>;
			xlnx,gen-f1-vsync-hstart = <1280>;
			xlnx,gen-f0-vsync-hend = <1280>;
		};
		misc_clk_3: misc_clk_3 {
			compatible = "fixed-clock";
			clock-frequency = <74250000>;
			#clock-cells = <0>;
		};
		mipi_csi2_rx_subsyst_0_rx: mipi_csi2_rx_ctrl@0 {
			xlnx,csi-vc-off-0 = <1>;
			xlnx,csi-opt3-fixedlanes = <1>;
			compatible = "xlnx,mipi-csi2-rx-ctrl-1.0";
			xlnx,axis-tuser-width = <96>;
			xlnx,is-7series;
			xlnx,csi-vc-off-1 = <2>;
			xlnx,csi-vc-off-2 = <3>;
			xlnx,csi-vc-off-3 = <4>;
			xlnx,csi2rx-dbg = <0>;
			xlnx,cmn-proj-family = <0>;
			xlnx,rable = <0>;
			xlnx,csi-vc-off-4 = <5>;
			xlnx,csi-opt1-regs = <0>;
			xlnx,disable-lite = <0>;
			xlnx,csi-vc-off-5 = <6>;
			xlnx,csi-lanes = <2>;
			xlnx,csi-en-vc-support = <1>;
			xlnx,ip-name = "mipi_csi2_rx_ctrl";
			xlnx,csi-vc-off-6 = <7>;
			reg = <0x00000000 0x1000>;
			xlnx,axis-fifo-depth = <2048>;
			clocks = <&misc_clk_2>, <&misc_clk_4>, <&misc_clk_4>, <&misc_clk_1>, <&misc_clk_0>, <&misc_clk_1>;
			xlnx,mipi-slv-int = <0>;
			xlnx,hs-line-rate = <800>;
			xlnx,csi-vc-off-7 = <8>;
			xlnx,axis-fifo-dcnt-width = <11>;
			xlnx,csi-vc-off-8 = <9>;
			xlnx,csi-offload-nonimage = <0>;
			xlnx,csi-inv-shutdown = <1>;
			xlnx,csi-fixed-vc = <0>;
			xlnx,csi-filter-userdatatype = <0>;
			xlnx,csi-vc-off-9 = <10>;
			xlnx,csi-vc-off-10 = <11>;
			xlnx,axis-tdest-width = <4>;
			xlnx,edk-iptype = "PERIPHERAL";
			xlnx,csi-vc-off-11 = <12>;
			xlnx,csi-vc-off-12 = <13>;
			xlnx,axis-tdata-width = <64>;
			xlnx,csi-vc-off-13 = <14>;
			xlnx,csi-opt2-crc = <0>;
			status = "okay";
			clock-names = "core_clk" , "dl0_rxbyteclkhs" , "dl1_rxbyteclkhs" , "m_axis_aclk" , "s_axi_aclk" , "video_aclk";
			xlnx,csi-vc-off-14 = <15>;
			xlnx,cmn-inc-vfb;
			xlnx,hp-io-bank-selection = <46>;
			xlnx,name = "mipi_csi2_rx_subsyst_0_rx";
		};
		misc_clk_2: misc_clk_2 {
			compatible = "fixed-clock";
			clock-frequency = <200000000>;
			#clock-cells = <0>;
		};
		misc_clk_4: misc_clk_4 {
			compatible = "fixed-clock";
			clock-frequency = <100000000>;
			#clock-cells = <0>;
		};
		misc_clk_0: misc_clk_0 {
			compatible = "fixed-clock";
			clock-frequency = <50000000>;
			#clock-cells = <0>;
		};
		misc_clk_1: misc_clk_1 {
			compatible = "fixed-clock";
			clock-frequency = <150000000>;
			#clock-cells = <0>;
		};
	};
};
